# ATtiny861 device description
Architecture: AVR8; Family: tinyAVR
Registers are 8-bit, access not given, no defined reset value unless marked. A register's access mark holds for its fields unless they carry their own. Offsets are from the block's base; [hi:lo] are bit positions.

## WDT — Watchdog Timer
Instances: WDT 0x00
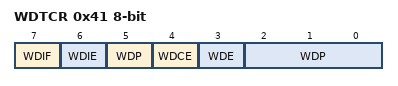
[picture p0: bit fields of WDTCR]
0x41 WDTCR — Watchdog Timer Control Register
  [7] WDIF — Watchdog Timeout Interrupt Flag
  [6] WDIE — Watchdog Timeout Interrupt Enable
  [4] WDCE — Watchdog Change Enable
  [3] WDE — Watch Dog Enable
  [5,2:0] WDP — Watchdog Timer Prescaler Bits
    0=Oscillator Cycles 2K; 1=Oscillator Cycles 4K; 2=Oscillator Cycles 8K; 3=Oscillator Cycles 16K; 4=Oscillator Cycles 32K; 5=Oscillator Cycles 64K; 6=Oscillator Cycles 128K; 7=Oscillator Cycles 256K; 8=Oscillator Cycles 512K; 9=Oscillator Cycles 1024K

## TC0 (TC8 module) — Timer/Counter, 8-bit
Instances: TC0 0x00
0x32 OCR0B — Timer/Counter0 Output Compare Register
0x33 OCR0A — Timer/Counter0 Output Compare Register
0x34 TCNT0H — Timer/Counter0 High
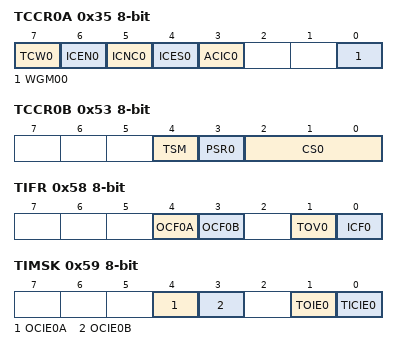
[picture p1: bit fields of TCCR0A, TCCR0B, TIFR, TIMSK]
0x35 TCCR0A — Timer/Counter Control Register A
  [7] TCW0 — Timer/Counter 0 Width
  [6] ICEN0 — Input Capture Mode Enable
  [5] ICNC0 — Input Capture Noice Canceler
  [4] ICES0 — Input Capture Edge Select
  [3] ACIC0 — Analog Comparator Input Capture Enable
  [0] WGM00 — Waveform Generation Mode
0x52 TCNT0L — Timer/Counter0 Low
0x53 TCCR0B — Timer/Counter Control Register B
  [4] TSM — Timer/Counter Synchronization Mode
  [3] PSR0 — Timer/Counter 0 Prescaler Reset
  [2:0] CS0 — Clock Select
    0=No Clock Source (Stopped); 1=Running, No Prescaling; 2=Running, CLK/8; 3=Running, CLK/64; 4=Running, CLK/256; 5=Running, CLK/1024; 6=Running, ExtClk Tx Falling Edge; 7=Running, ExtClk Tx Rising Edge
0x58 TIFR — Timer/Counter0 Interrupt Flag register
  [4] OCF0A — Timer/Counter0 Output Compare Flag 0A
  [3] OCF0B — Timer/Counter0 Output Compare Flag 0B
  [1] TOV0 — Timer/Counter0 Overflow Flag
  [0] ICF0 — Timer/Counter0 Input Capture Flag
0x59 TIMSK — Timer/Counter Interrupt Mask Register
  [4] OCIE0A — Timer/Counter0 Output Compare Match A Interrupt Enable
  [3] OCIE0B — Timer/Counter0 Output Compare Match B Interrupt Enable
  [1] TOIE0 — Timer/Counter0 Overflow Interrupt Enable
  [0] TICIE0 — Timer/Counter0 Input Capture Interrupt Enable

## TC1 (TC16 module) — Timer/Counter, 16-bit
Instances: TC1 0x00
0x20 TCCR1E — Timer/Counter1 Control Register E
  [5:0] OC1OE — Ouput Compare Override Enable Bits
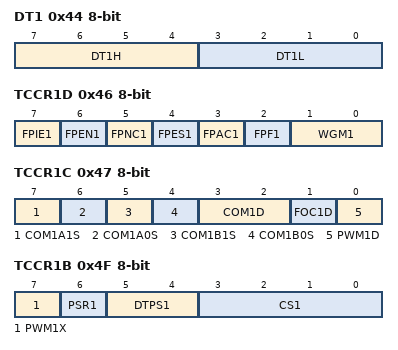
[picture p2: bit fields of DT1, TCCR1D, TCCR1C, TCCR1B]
0x44 DT1 — Timer/Counter 1 Dead Time Value
  [7:4] DT1H, [3:0] DT1L
0x45 TC1H bits used 1:0 — Timer/Counter 1 Register High
0x46 TCCR1D — Timer/Counter Control Register D
  [7] FPIE1 — Fault Protection Interrupt Enable
  [6] FPEN1 — Fault Protection Mode Enable
  [5] FPNC1 — Fault Protection Noise Canceler
  [4] FPES1 — Fault Protection Edge Select
  [3] FPAC1 — Fault Protection Analog Comparator Enable
  [2] FPF1 — Fault Protection Interrupt Flag
  [1:0] WGM1 — Waveform Generation Mode Bit
    0=Fast PWM (NB! PWMx must be set!); 1=Phase and Frequency Correct PWM; 2=PWM6/Single-slope; 3=PWM6/Dual-slope
0x47 TCCR1C — Timer/Counter Control Register C
  [7] COM1A1S — COM1A1 Shadow Bit
  [6] COM1A0S — COM1A0 Shadow Bit
  [5] COM1B1S — COM1B1 Shadow Bit
  [4] COM1B0S — COM1B0 Shadow Bit
  [3:2] COM1D — Comparator D output mode
  [1] FOC1D — Force Output Compare Match 1D
  [0] PWM1D — Pulse Width Modulator D Enable
0x4A OCR1D — Output compare register
0x4B OCR1C — Output compare register
0x4C OCR1B — Output Compare Register
0x4D OCR1A — Output Compare Register
0x4E TCNT1 — Timer/Counter Register
0x4F TCCR1B — Timer/Counter Control Register B
  [7] PWM1X — PWM Inversion Mode
  [6] PSR1 — Timer/Counter 1 Prescaler reset
  [5:4] DTPS1 — Dead Time Prescaler
    0=1x; 1=2x; 2=4x; 3=8x
  [3:0] CS1 — Clock Select Bits
    0=No Clock Source (Stopped); 1=Running, No Prescaling; 2=Running, CLK/2; 3=Running, CLK/4; 4=Running, CLK/8; 5=Running, CLK/16; 6=Running, CLK/32; 7=Running, CLK/64; 8=Running, CLK/128; 9=Running, CLK/256; 10=Running, CLK/512; 11=Running, CLK/1024; 12=Running, CLK/2048; 13=Running, CLK/4096; 14=Running, CLK/8192; 15=Running, CLK/16384
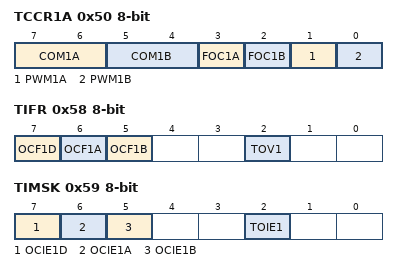
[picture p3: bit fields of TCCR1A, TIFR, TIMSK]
0x50 TCCR1A — Timer/Counter Control Register A
  [7:6] COM1A — Compare Output Mode, Bits
  [5:4] COM1B — Compare Output Mode, Bits
  [3] FOC1A — Force Output Compare Match 1A
  [2] FOC1B — Force Output Compare Match 1B
  [1] PWM1A — Pulse Width Modulator Enable
  [0] PWM1B — Pulse Width Modulator Enable
0x58 TIFR — Timer/Counter Interrupt Flag Register
  [7] OCF1D — Timer/Counter1 Output Compare Flag 1D
  [6] OCF1A — Timer/Counter1 Output Compare Flag 1A
  [5] OCF1B — Timer/Counter1 Output Compare Flag 1B
  [2] TOV1 — Timer/Counter1 Overflow Flag
0x59 TIMSK — Timer/Counter Interrupt Mask Register
  [7] OCIE1D — OCIE1D: Timer/Counter1 Output Compare Interrupt Enable
  [6] OCIE1A — OCIE1A: Timer/Counter1 Output Compare Interrupt Enable
  [5] OCIE1B — OCIE1A: Timer/Counter1 Output Compare B Interrupt Enable
  [2] TOIE1 — Timer/Counter1 Overflow Interrupt Enable

## BOOT_LOAD — Bootloader
Instances: BOOT_LOAD 0x00
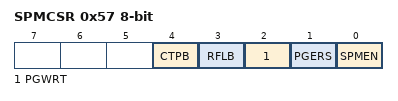
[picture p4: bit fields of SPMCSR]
0x57 SPMCSR — Store Program Memory Control Register
  [4] CTPB — Clear temporary page buffer
  [3] RFLB — Read fuse and lock bits
  [2] PGWRT — Page Write
  [1] PGERS — Page Erase
  [0] SPMEN — Store Program Memory Enable

## EXINT — External Interrupts
Instances: EXINT 0x00
0x42 PCMSK1 — Pin Change Enable Mask 1
0x43 PCMSK0 — Pin Change Enable Mask 0
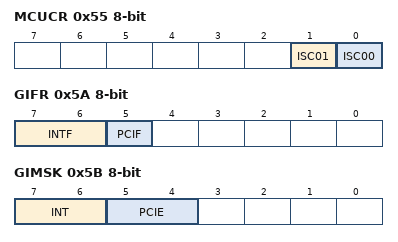
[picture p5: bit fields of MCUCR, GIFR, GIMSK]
0x55 MCUCR — MCU Control Register
  [1] ISC01 — Interrupt Sense Control 0 Bit 1
  [0] ISC00 — Interrupt Sense Control 0 Bit 0
    0=Low Level of INTX; 1=Any Logical Change of INTX; 2=Falling Edge of INTX; 3=Rising Edge of INTX
0x5A GIFR — General Interrupt Flag register
  [7:6] INTF — External Interrupt Flags
  [5] PCIF — Pin Change Interrupt Flag
0x5B GIMSK — General Interrupt Mask Register
  [7:6] INT — External Interrupt Request 1 Enable
  [5:4] PCIE — Pin Change Interrupt Enables

## CPU — CPU Registers
Instances: CPU 0x00
Parameters: CORE_VERSION=V2, NEW_INSTRUCTIONS=lpm rd,z+
0x2A GPIOR0 — General purpose register 0
0x2B GPIOR1 — General Purpose register 1
0x2C GPIOR2 — General Purpose IO register 2
0x40 DWDR — debugWire data register
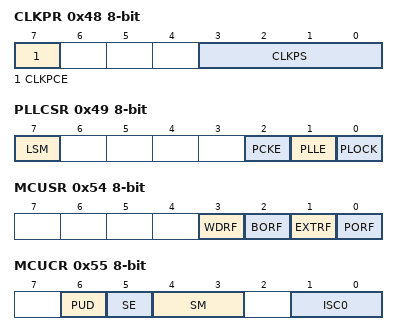
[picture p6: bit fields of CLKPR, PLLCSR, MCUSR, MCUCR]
0x48 CLKPR — Clock Prescale Register
  [7] CLKPCE — Clock Prescaler Change Enable
  [3:0] CLKPS — Clock Prescaler Select Bits
    0=1; 1=2; 2=4; 3=8; 4=16; 5=32; 6=64; 7=128; 8=256
0x49 PLLCSR — PLL Control and status register
  [7] LSM — Low speed mode
  [2] PCKE — PCK Enable
  [1] PLLE — PLL Enable
  [0] PLOCK — PLL Lock detector
0x51 OSCCAL — Oscillator Calibration Register
  [7:0] OSCCAL — Oscillator Calibration
0x54 MCUSR — MCU Status register
  [3] WDRF — Watchdog Reset Flag
  [2] BORF — Brown-out Reset Flag
  [1] EXTRF — External Reset Flag
  [0] PORF — Power-On Reset Flag
0x55 MCUCR — MCU Control Register
  [6] PUD — Pull-up Disable
  [5] SE — Sleep Enable
  [4:3] SM — Sleep Mode Select Bits
    0=IDLE; 1=ADC (ADC Noise Reduction (If Available)); 2=PDOWN (Power Down); 3=STDBY (Standby)
  [1:0] ISC0 — Interrupt Sense Control 0 bits
    0=Low Level of INTX; 1=Any Logical Change in INTX; 2=Falling Edge of INTX; 3=Rising Edge of INTX
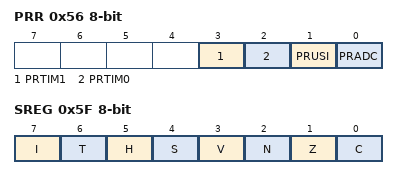
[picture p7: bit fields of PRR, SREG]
0x56 PRR — Power Reduction Register
  [3] PRTIM1 — Power Reduction Timer/Counter1
  [2] PRTIM0 — Power Reduction Timer/Counter0
  [1] PRUSI — Power Reduction USI
  [0] PRADC — Power Reduction ADC
0x5D SP 16-bit bits used 9:0 — Stack Pointer Bytes
0x5F SREG — Status Register
  [7] I — Global Interrupt Enable
  [6] T — Bit Copy Storage
  [5] H — Half Carry Flag
  [4] S — Sign Bit
  [3] V — Two's Complement Overflow Flag
  [2] N — Negative Flag
  [1] Z — Zero Flag
  [0] C — Carry Flag
Value list OSCCAL_VALUE_ADDRESSES: 0=8_0_MHz
